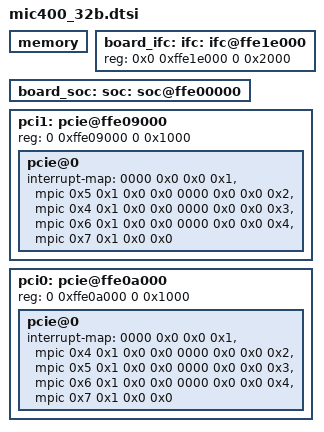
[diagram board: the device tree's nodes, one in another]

memory {
	device_type = "memory";
};

board_ifc: ifc: ifc@ffe1e000 {

	/* NAND Flash */
	ranges = <0x1 0x0 0x0 0xff800000 0x00010000>;
	reg = <0x0 0xffe1e000 0 0x2000>;
};

board_soc: soc: soc@ffe00000 {
	ranges = <0x0 0x0 0xffe00000 0x100000>;
};

pci1: pcie@ffe09000 {
	reg = <0 0xffe09000 0 0x1000>;
	ranges = <0x2000000 0x0 0xfa000000 0 0xfa000000 0x0 0x02000000
		  0x1000000 0x0 0x00000000 0 0xffc10000 0x0 0x10000>;
	pcie@0 {
		interrupt-map = <
		/* IDSEL 0x0 */
		0000 0x0 0x0 0x1 &mpic 0x5 0x1 0x0 0x0
		0000 0x0 0x0 0x2 &mpic 0x4 0x1 0x0 0x0
		0000 0x0 0x0 0x3 &mpic 0x6 0x1 0x0 0x0
		0000 0x0 0x0 0x4 &mpic 0x7 0x1 0x0 0x0
		>;

		ranges = <0x2000000 0x0 0xfa000000
			  0x2000000 0x0 0xfa000000
			  0x0 0x02000000

			  0x1000000 0x0 0x0
			  0x1000000 0x0 0x0
			  0x0 0x100000>;
	};
};

pci0: pcie@ffe0a000 {
	reg = <0 0xffe0a000 0 0x1000>;
	ranges = <0x2000000 0x0 0xf8000000 0 0xf8000000 0x0 0x02000000
		  0x1000000 0x0 0x00000000 0 0xffc00000 0x0 0x10000>;
	pcie@0 {
		interrupt-map = <
		/* IDSEL 0x0 */
		0000 0x0 0x0 0x1 &mpic 0x4 0x1 0x0 0x0
		0000 0x0 0x0 0x2 &mpic 0x5 0x1 0x0 0x0
		0000 0x0 0x0 0x3 &mpic 0x6 0x1 0x0 0x0
		0000 0x0 0x0 0x4 &mpic 0x7 0x1 0x0 0x0
		>;
		ranges = <0x2000000 0x0 0xf8000000
			  0x2000000 0x0 0xf8000000
			  0x0 0x02000000

			  0x1000000 0x0 0x0
			  0x1000000 0x0 0x0
			  0x0 0x100000>;
	};
};
